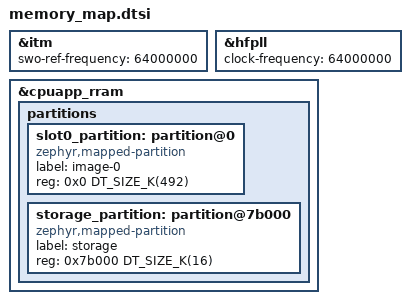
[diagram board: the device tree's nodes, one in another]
/*
 * Copyright (c) 2026 Nordic Semiconductor ASA
 *
 * SPDX-License-Identifier: LicenseRef-Nordic-5-Clause
 */

/*
 * nRF54L Series SoCs start at 64 MHz and may switch to 128 MHz during init.
 * Zephyr sets 128 MHz at boot by default (SoC-level devicetree).
 * 64 MHz is enough for 1000 Hz HID reporting and lowers power vs 128 MHz.
 */


&itm {
	swo-ref-frequency = <64000000>;
};

&hfpll {
	clock-frequency = <64000000>;
};

/* Debug build without MCUboot. */
&cpuapp_rram {
	/delete-node/ partitions;

	partitions {
		#address-cells = <1>;
		#size-cells = <1>;
		ranges;

		slot0_partition: partition@0 {
			compatible = "zephyr,mapped-partition";
			label = "image-0";
			reg = <0x0 DT_SIZE_K(492)>;
		};

		storage_partition: partition@7b000 {
			compatible = "zephyr,mapped-partition";
			label = "storage";
			reg = <0x7b000 DT_SIZE_K(16)>;
		};
	};
};
